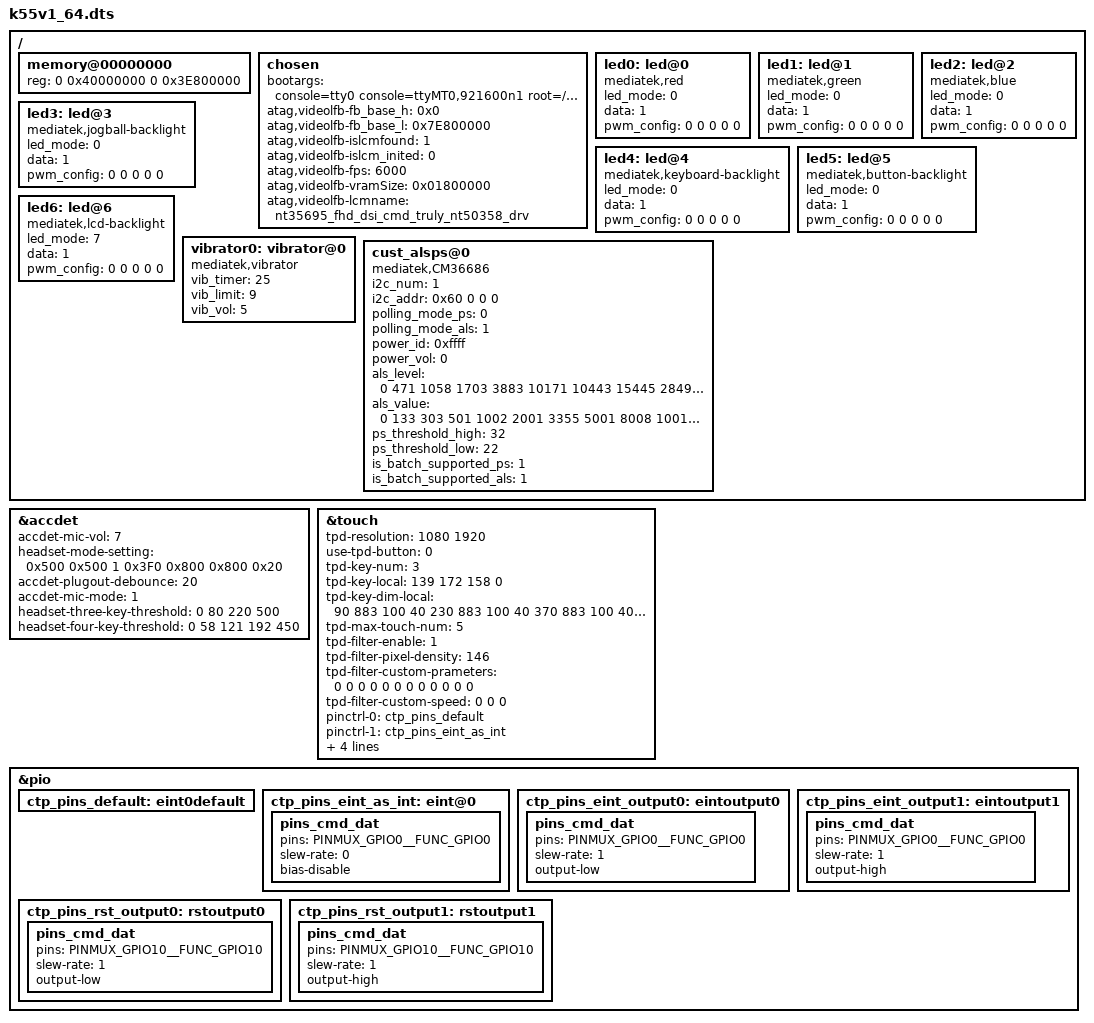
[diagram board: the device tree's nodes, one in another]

/dts-v1/;

#include "mt6755.dtsi"
#include "cust_i2c_k55v1_64.dtsi"
#include "cust_kpd_k55v1_64.dtsi"

/ {
	memory@00000000 {
		device_type = "memory";
		reg = <0 0x40000000 0 0x3E800000>;
	};
	/* chosen */
	chosen {
		bootargs = "console=tty0 console=ttyMT0,921600n1 root=/dev/ram initrd=0x44000000,0x4B434E loglevel=8";

		/* fpga may has no lk, we need to specify display info here */
		/* fb buffer is reserved using this dts by memory node above */
		atag,videolfb-fb_base_h = <0x0>;
		atag,videolfb-fb_base_l = <0x7E800000>;
		atag,videolfb-islcmfound = <1>;
		/* because no lk, so lcm is not inited */
		atag,videolfb-islcm_inited = <0>;
		atag,videolfb-fps= <6000>;
		atag,videolfb-vramSize= <0x01800000>;
		atag,videolfb-lcmname= "nt35695_fhd_dsi_cmd_truly_nt50358_drv";
	};
	led0:led@0 {
		compatible = "mediatek,red";
		led_mode = <0>;
		data = <1>;
		pwm_config = <0 0 0 0 0>;
	};
	led1:led@1 {
		compatible = "mediatek,green";
		led_mode = <0>;
		data = <1>;
		pwm_config = <0 0 0 0 0>;
	};
	led2:led@2 {
		compatible = "mediatek,blue";
		led_mode = <0>;
		data = <1>;
		pwm_config = <0 0 0 0 0>;
	};
	led3:led@3 {
		compatible = "mediatek,jogball-backlight";
		led_mode = <0>;
		data = <1>;
		pwm_config = <0 0 0 0 0>;
	};
	led4:led@4 {
		compatible = "mediatek,keyboard-backlight";
		led_mode = <0>;
		data = <1>;
		pwm_config = <0 0 0 0 0>;
	};
	led5:led@5 {
		compatible = "mediatek,button-backlight";
		led_mode = <0>;
		data = <1>;
		pwm_config = <0 0 0 0 0>;
	};
	led6:led@6 {
		compatible = "mediatek,lcd-backlight";
		led_mode = <7>;
		data = <1>;
		pwm_config = <0 0 0 0 0>;
	};
	vibrator0:vibrator@0 {
		compatible = "mediatek,vibrator";
		vib_timer = <25>;
		vib_limit = <9>;
		vib_vol= <5>;
	};
/*  start sensor */
	cust_alsps@0 {
		compatible				= "mediatek,CM36686";
		i2c_num					= <1>;
		i2c_addr				= <0x60 0 0 0>;
		polling_mode_ps			= <0>;
		polling_mode_als		= <1>;
		power_id			= <0xffff>;
		power_vol			= <0>;
/* Total has 15 level*/
		als_level  = <0 471 1058 1703 3883 10171 10443 15445 28499 35153 41421 59194 65535 65535 65535>;
/*  Total has 16 range*/
		als_value  = <0 133 303 501 1002 2001 3355 5001 8008 10010 12000 16010 20010 20010 20010 20010>;
		ps_threshold_high		=  <32>;
		ps_threshold_low		=  <22>;
		is_batch_supported_ps	= <1>;
		is_batch_supported_als	= <1>;
	};
/* end sensor */
};
&accdet {
		accdet-mic-vol = <7>;
		headset-mode-setting = <0x500 0x500 1 0x3F0 0x800 0x800 0x20>;
		accdet-plugout-debounce = <20>;
		/*1:ACC mode, 2:low cost without in bias, 6:low cost with in bias*/
		accdet-mic-mode = <1>;
		/*0--MD_MAX--UP_MAX--DW_MAX*/
		headset-three-key-threshold = <0 80 220 500>;
		/*0--MD_MAX--VOICE_MAX--UP_MAX--DW_MAX*/
		headset-four-key-threshold = <0 58 121 192 450>;
};

/* TOUCH start */
&touch {
	tpd-resolution = <1080 1920>;
	use-tpd-button = <0>;
	tpd-key-num = <3>;
	tpd-key-local= <139 172 158 0>;
	tpd-key-dim-local = <90 883 100 40 230 883 100 40 370 883 100 40 0 0 0 0>;
	tpd-max-touch-num = <5>;
	tpd-filter-enable = <1>;
	tpd-filter-pixel-density = <146>;
	tpd-filter-custom-prameters = <0 0 0 0 0 0 0 0 0 0 0 0>;
	tpd-filter-custom-speed = <0 0 0>;
	pinctrl-names = "default", "state_eint_as_int", "state_eint_output0", "state_eint_output1",
		"state_rst_output0", "state_rst_output1";
	pinctrl-0 = <&ctp_pins_default>;
	pinctrl-1 = <&ctp_pins_eint_as_int>;
	pinctrl-2 = <&ctp_pins_eint_output0>;
	pinctrl-3 = <&ctp_pins_eint_output1>;
	pinctrl-4 = <&ctp_pins_rst_output0>;
	pinctrl-5 = <&ctp_pins_rst_output1>;
	status = "okay";
};
&pio {
	ctp_pins_default: eint0default {
	};
	ctp_pins_eint_as_int: eint@0 {
		pins_cmd_dat {
			pins = <PINMUX_GPIO0__FUNC_GPIO0>;
			slew-rate = <0>;
			bias-disable;
		};
	};
	ctp_pins_eint_output0: eintoutput0 {
		pins_cmd_dat {
			pins = <PINMUX_GPIO0__FUNC_GPIO0>;
			slew-rate = <1>;
			output-low;
		};
	};
	ctp_pins_eint_output1: eintoutput1 {
		pins_cmd_dat {
			pins = <PINMUX_GPIO0__FUNC_GPIO0>;
			slew-rate = <1>;
			output-high;
		};
	};
	ctp_pins_rst_output0: rstoutput0 {
		pins_cmd_dat {
			pins = <PINMUX_GPIO10__FUNC_GPIO10>;
			slew-rate = <1>;
			output-low;
		};
	};
	ctp_pins_rst_output1: rstoutput1 {
		pins_cmd_dat {
			pins = <PINMUX_GPIO10__FUNC_GPIO10>;
			slew-rate = <1>;
			output-high;
		};
	};
};
/* TOUCH end */
